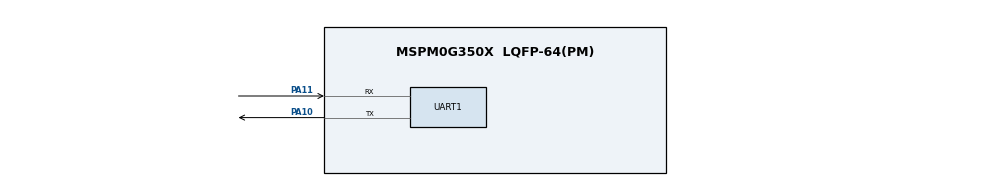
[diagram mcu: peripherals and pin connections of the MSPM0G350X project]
/**
 * @cliArgs --device "MSPM0G350X" --part "Default" --package "LQFP-64(PM)" --product "mspm0_sdk@2.09.00.02"
 * @versions {"tool":"1.25.0+4268"}
 */

/**
 * Import the modules used in this configuration.
 */
const Board         = scripting.addModule("/ti/driverlib/Board");
const CRC           = scripting.addModule("/ti/driverlib/CRC");
const SYSCTL        = scripting.addModule("/ti/driverlib/SYSCTL");
const UART          = scripting.addModule("/ti/driverlib/UART", {}, false);
const UART1         = UART.addInstance();
const ProjectConfig = scripting.addModule("/ti/project_config/ProjectConfig");

/**
 * Write custom configuration values to the imported modules.
 */
Board.configureUnused = true;

CRC.polynomial = "16_POLYNOMIAL";
CRC.seed       = 0xFFFF;


UART1.$name                    = "UART_0";
UART1.enableFIFO               = true;
UART1.rxFifoThreshold          = "DL_UART_RX_FIFO_LEVEL_ONE_ENTRY";
UART1.txFifoThreshold          = "DL_UART_TX_FIFO_LEVEL_3_4_EMPTY";
UART1.targetBaudRate           = 115200;
UART1.enableDMARX              = false;
UART1.enableDMATX              = false;
UART1.enabledInterrupts        = ["RX","TX"];
UART1.peripheral.$assign       = "UART0";
UART1.peripheral.rxPin.$assign = "PA11";
UART1.peripheral.txPin.$assign = "PA10";
UART1.txPinConfig.$name        = "ti_driverlib_gpio_GPIOPinGeneric0";
UART1.rxPinConfig.$name        = "ti_driverlib_gpio_GPIOPinGeneric1";

/**
 * Pinmux solution for unlocked pins/peripherals. This ensures that minor changes to the automatic solver in a future
 * version of the tool will not impact the pinmux you originally saw.  These lines can be completely deleted in order to
 * re-solve from scratch.
 */
Board.peripheral.$suggestSolution          = "DEBUGSS";
Board.peripheral.swclkPin.$suggestSolution = "PA20";
Board.peripheral.swdioPin.$suggestSolution = "PA19";
CRC.peripheral.$suggestSolution            = "CRC";
SYSCTL.peripheral.$suggestSolution         = "SYSCTL";
